# DSP2_EDMA_TPCC register map
Vendor: Texas Instruments
Registers are 32-bit, read-write, reset values left out (the file's numbers can be read two ways) unless marked. A register's access mark holds for its fields unless they carry their own. Offsets are as the file gives them; [hi:lo] are bit positions; {n}, {i} and the like mark numbered series; 'fields as' and 'values as' point back to an identical list.

## DSP2_EDMA_TPCC (part 2 of 2)
0x00 EDMA_TPCC_PID ro — Peripheral ID Register
  [31:0] REVISION — IP revision
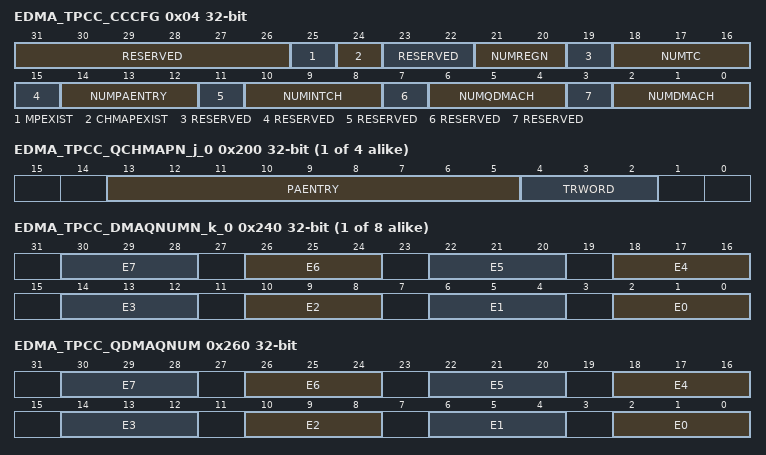
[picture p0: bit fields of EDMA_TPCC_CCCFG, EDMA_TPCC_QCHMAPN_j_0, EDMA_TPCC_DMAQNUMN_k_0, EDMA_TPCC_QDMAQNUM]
0x04 EDMA_TPCC_CCCFG ro — CC Configuration Register
  [31:26] RESERVED — Reads return 0's
  [25] MPEXIST — Memory Protection Existence
    0=No_memory_protection; 1=Memory_Protection_logic_included
  [24] CHMAPEXIST — Channel Mapping Existence
    0=No_Channel_mapping; 1=Channel_mapping_logic_included
  [23:22] RESERVED — Reads return 0's
  [21:20] NUMREGN — Number of MP and Shadow regions
    0=NUMREG0 (0 Regions); 1=NUMREG2 (2 Regions); 2=NUMREG8 (4 Regions); 3=NUMREG4 (8 Regions)
  [19] RESERVED — Reads return 0's
  [18:16] NUMTC — Number of Queues/Number of TCs
    {v}={v+1} TC/Event Queue (v=0..7)
  [15] RESERVED — Reads return 0's
  [14:12] NUMPAENTRY — Number of PaRAM entries
    0=NUMPARAMENTRIES32 (16 entries); 1=NUMPARAMENTRIES16 (32 entries); 2=NUMPARAMENTRIES64 (64 entries); 3=NUMPARAMENTRIES256 (128 entries); 4=NUMPARAMENTRIES512 (256 entries); 5=NUMPARAMENTRIES128 (512 entries)
  [11] RESERVED — Reads return 0's
  [10:8] NUMINTCH — Number of Interrupt Channels
    1=8 Interrupt channels; 2=16 Interrupt channels; 3=32 Interrupt channels; 4=64 Interrupt channels
  [7] RESERVED — reads return 0's
  [6:4] NUMQDMACH — Number of QDMA Channels
    0=No QDMA Channels; 1=2 QDMA Channels; 2=4 QDMA Channels; 3=6 QDMA Channels; 4=8 QDMA Channels
  [3] RESERVED — reads return 0's
  [2:0] NUMDMACH — Number of DMA Channels
    0=No DMA Channels; 1=4 DMA Channels; 2=8 DMA Channels; 3=16 DMA Channels; 4=32 DMA Channels; 5=64 DMA Channels
0xFC EDMA_TPCC_CLKGDIS access per field — Auto Clock Gate Disable
  [0] CLKGDIS rw
{0x100+4i} EDMA_TPCC_DCHMAPN_m_{i} access per field (i=0..63) — DMA Channel N Mapping Register
  [13:5] PAENTRY rw — PaRAM Entry number for DMA Channel N.
{0x200+4i} EDMA_TPCC_QCHMAPN_j_{i} access per field (i=0..3) — QDMA Channel N Mapping Register
  [13:5] PAENTRY rw — PaRAM Entry number for QDMA Channel N.
  [4:2] TRWORD rw — TRWORD points to the specific trigger word of the PaRAM Entry defined by PAENTRY. A write to the trigger word results in a QDMA Event being recognized.
{0x240+4i} EDMA_TPCC_DMAQNUMN_k_{i} access per field (i=0..7) — DMA Queue Number Register n Contains the Event queue number to be used for the corresponding DMA Channel.
  [4n+2:4n] E{n} rw (n=0..7) — DMA Queue Number for event #{n}
0x260 EDMA_TPCC_QDMAQNUM access per field — QDMA Queue Number Register Contains the Event queue number to be used for the corresponding QDMA Channel.
  [4n+2:4n] E{n} rw (n=0..7) — QDMA Queue Number for event #{n}
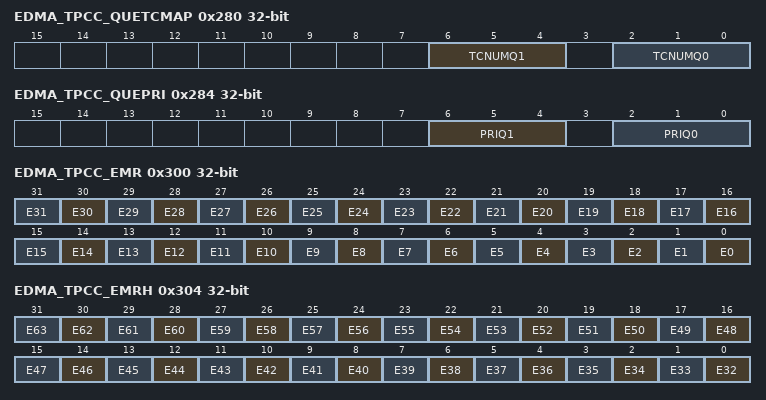
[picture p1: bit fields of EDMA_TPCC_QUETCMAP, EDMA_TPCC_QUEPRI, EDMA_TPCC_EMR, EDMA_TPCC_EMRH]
0x280 EDMA_TPCC_QUETCMAP access per field — Queue to TC Mapping
  [6:4] TCNUMQ1 rw — TC Number for Queue N: Defines the TC number that Event Queue N TRs are written to.
  [2:0] TCNUMQ0 rw — TC Number for Queue N: Defines the TC number that Event Queue N TRs are written to.
0x284 EDMA_TPCC_QUEPRI access per field — Queue Priority
  [6:4] PRIQ1 rw — Priority Level for Queue 1 Dictates the priority level used for the OPTIONS field programmation for Qn TRs. Sets the priority used for TC read and write commands.
  [2:0] PRIQ0 rw — Priority Level for Queue 0 Dictates the priority level used for the OPTIONS field programmation for Qn TRs. Sets the priority used for TC read and write commands.
0x300 EDMA_TPCC_EMR ro — Event Missed Register: The Event Missed register is set if 2 events are received without the first event being cleared or if a Null TR is serviced. Chained events (CER), Set Events (ESR), and normal events (ER) are treated individually. If any bit in the EMR register is set (and all errors (including / ) were previously clear), then an error will be signaled with TPCC error interrupt.
  [n] E{n} (n=0..31) — Event Missed #{n}
0x304 EDMA_TPCC_EMRH ro — Event Missed Register (High Part): The Event Missed register is set if 2 events are received without the first event being cleared or if a Null TR is serviced. Chained events (CER), Set Events (ESR), and normal events (ER) are treated individually. If any bit in the EMR register is set (and all errors (including / ) were previously clear), then an error will be signaled with TPCC error interrupt.
  [n-32] E{n} (n=32..63) — Event Missed #{n}
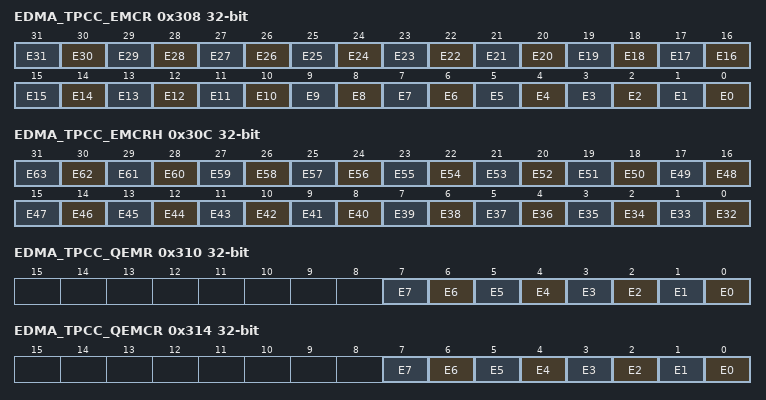
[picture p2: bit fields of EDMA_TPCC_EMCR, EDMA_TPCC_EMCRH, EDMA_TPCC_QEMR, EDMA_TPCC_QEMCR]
0x308 EDMA_TPCC_EMCR wo — Event Missed Clear Register: CPU write of '1' to the.En bit causes the .En bit to be cleared. CPU write of '0' has no effect.. All error bits must be cleared before additional error interrupts will be asserted by CC.
  [n] E{n} (n=0..31) — Event Missed Clear #{n}
0x30C EDMA_TPCC_EMCRH wo — Event Missed Clear Register (High Part): CPU write of '1' to the.En bit causes the .En bit to be cleared. CPU write of '0' has no effect. All error bits must be cleared before additional error interrupts will be asserted by CC.
  [n-32] E{n} (n=32..63) — Event Missed Clear #{n}
0x310 EDMA_TPCC_QEMR ro — QDMA Event Missed Register: The QDMA Event Missed register is set if 2 QDMA events are detected without the first event being cleared or if a Null TR is serviced. If any bit in the register is set (and all errors (including / ) were previously clear), then an error will be signaled with TPCC error interrupt.
  [n] E{n} (n=0..7) — Event Missed #{n}
0x314 EDMA_TPCC_QEMCR access per field — QDMA Event Missed Clear Register: CPU write of '1' to the.En bit causes the .En bit to be cleared. CPU write of '0' has no effect. All error bits must be cleared before additional error interrupts will be asserted by CC.
  [n] E{n} wo (n=0..7) — Event Missed Clear #{n}
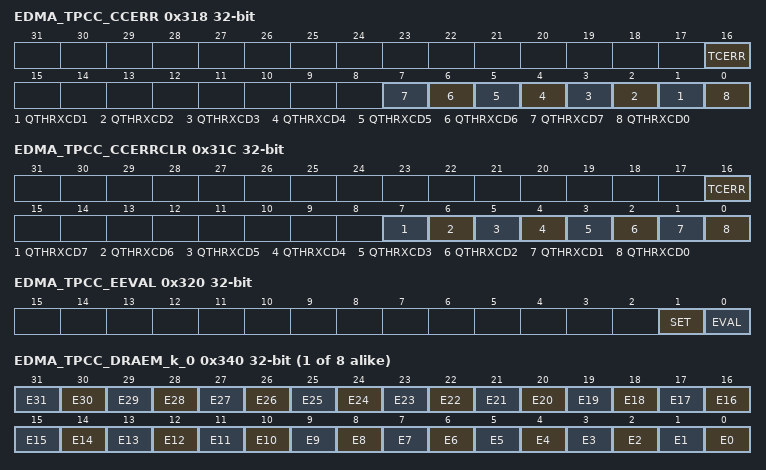
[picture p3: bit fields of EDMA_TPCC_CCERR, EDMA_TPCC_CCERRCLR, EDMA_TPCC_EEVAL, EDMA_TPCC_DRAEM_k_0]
0x318 EDMA_TPCC_CCERR ro — CC Error Register
  [16] TCERR — Transfer Completion Code ErrorTCERR can be cleared by writing a '1' to corresponding bit in register. If any bit in the register is set (and all errors were previously clear), then an error will be signaled with TPCC error interrupt. .
    0=Total number of allowed TCCs outstanding has not been reached; 1=Total number of allowed TCCs has been reached
  [n] QTHRXCD{n} (n=1..7) — Queue Threshold Error for Q{n}QTHRXCD{n} can be cleared by writing a '1' to corresponding bit in register. If any bit in the register is set (and all errors (including /) were previously clear), then an error will be signaled with the TPCC error interrupt. .
    0=Watermark/threshold has not been exceeded; 1=Watermark/threshold_has_been_exceeded
  [0] QTHRXCD0 — Queue Threshold Error for Q0:QTHRXCD0 can be cleared by writing a '1' to corresponding bit in register. If any bit in the register is set (and all errors (including /) were previously clear), then an error will be signaled with the TPCC error interrupt. .
    values as QTHRXCD1
0x31C EDMA_TPCC_CCERRCLR access per field — CC Error Clear Register
  [16] TCERR wo — Clear Error forEDMA_TPCC_CCERR[16] TR.Write 0x1 to clear the value of[16] TCERR. . Write 0x0 have no affect. .
  [7] QTHRXCD7 wo — Clear error forEDMA_TPCC_CCERR[7]QTHRXCD7Write 0x0 have no affect. . Write 0x1 to clear the values of QSTAT7.WM, QSTAT7.THRXCD,[7] QTHRXCD7 .
  [6] QTHRXCD6 wo — Clear error forEDMA_TPCC_CCERR[6] QTHRXCD6Write 0x0 have no affect. . Write 0x1 to clear the values of QSTAT6.WM, QSTAT6.THRXCD,[6]QTHRXCD6 .
  [5] QTHRXCD5 wo — Clear error forEDMA_TPCC_CCERR[5] QTHRXCD5Write 0x0 have no affect. . Write 0x1 to clear the values of QSTAT5.WM, QSTAT5.THRXCD,[5]QTHRXCD5 .
  [4] QTHRXCD4 wo — Clear error forEDMA_TPCC_CCERR[4] QTHRXCD4:Write 0x0 have no affect. . Write 0x1 to clear the values of QSTAT4.WM, QSTAT4.THRXCD,[4] QTHRXCD4 .
  [3] QTHRXCD3 wo — Clear error forEDMA_TPCC_CCERR[3] QTHRXCD3Write 0x1 to clear the values of QSTAT3.WM, QSTAT3.THRXCD,[3] QTHRXCD3 . Write 0x0 have no affect. .
  [2] QTHRXCD2 wo — Clear error forEDMA_TPCC_CCERR[2] QTHRXCD2Write 0x0 have no affect. . Write 0x1 to clear the values of QSTAT2.WM, QSTAT2.THRXCD,[2] QTHRXCD2 .
  [1] QTHRXCD1 wo — Clear error forEDMA_TPCC_CCERR[1] QTHRXCD1Write 0x1 to clear the values of QSTAT1.WM, QSTAT1.THRXCD,[1] QTHRXCD1 . Write 0x0 have no affect. .
  [0] QTHRXCD0 wo — Clear error forEDMA_TPCC_CCERR[0] QTHRXCD0Write 0x0 have no affect. . Write 0x1 to clear the values of QSTAT0.WM, QSTAT0.THRXCD,[0] QTHRXCD0 .
0x320 EDMA_TPCC_EEVAL access per field — Error Eval Register
  [1] SET wo — Error Interrupt SetCPU writes 0x0 has no effect. . CPU writes 0x1 to the SET bit causes the TPCC error interrupt to be pulsed regardless of state of/, , or . .
  [0] EVAL wo — Error Interrupt EvaluateCPU writes 0x0 has no effect. . CPU writes 0x1 to the EVAL bit causes the TPCC error interrupt to be pulsed if any errors have not been cleared in the/, , or registers. The CPU must also write 0x1 after any error interrupts are serviced in order for subsequent interrupts to be asserted. .
{0x340+8i} EDMA_TPCC_DRAEM_k_{i} (i=0..7) — DMA Region Access enable for bit N in Region M: En = 0 : Accesses via Region M address space to Bit N in any DMA Channel Register are not allowed. Reads will return 'b0 on Bit N and writes will not modify the state of bit N. Enabled interrupt bits for bit N do not contribute to the generation of the TPCC region M interrupt. En = 1 : Accesses via Region M address space to Bit N in any DMA Channel Register are allowed. Reads will return the value from Bit N and writes will modify the state of bit N. Enabled interrupt bits for bit N do contribute to the generation of the TPCC region M interrupt.
  [n] E{n} (n=0..31) — DMA Region Access enable for Region M, bit #{n}
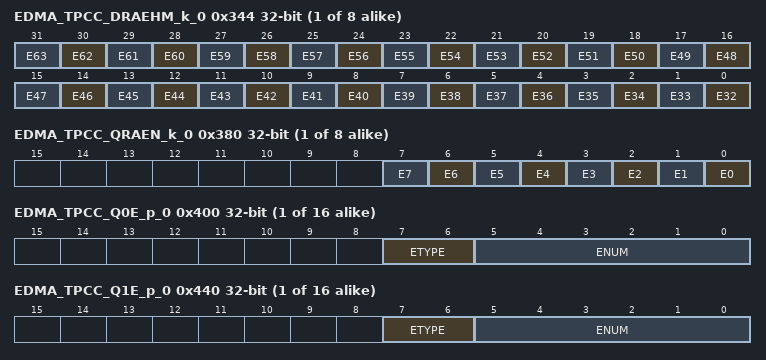
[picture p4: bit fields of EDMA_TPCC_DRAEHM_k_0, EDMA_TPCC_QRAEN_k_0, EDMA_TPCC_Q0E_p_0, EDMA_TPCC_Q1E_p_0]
{0x344+8i} EDMA_TPCC_DRAEHM_k_{i} (i=0..7) — DMA Region Access enable for bit N in Region M: En = 0 : Accesses via Region M address space to Bit N in any DMA Channel Register are not allowed. Reads will return 'b0 on Bit N and writes will not modify the state of bit N. Enabled interrupt bits for bit N do not contribute to the generation of the TPCC region M interrupt. En = 1 : Accesses via Region M address space to Bit N in any DMA Channel Register are allowed. Reads will return the value from Bit N and writes will modify the state of bit N. Enabled interrupt bits for bit N do contribute to the generation of the TPCC region M interrupt. En = 0 : Accesses via Region M address space to Bit N in any DMA Channel Register are not allowed. Reads will return 'b0 on Bit N and writes will not modify the state of bit N. Enabled interrupt bits for bit N do not contribute to the generation of the TPCC region M interrupt. En = 1 : Accesses via Region M address space to Bit N in any DMA Channel Register are allowed. Reads will return the value from Bit N and writes will modify the state of bit N. Enabled interrupt bits for bit N do contribute to the generation of the TPCC region M interrupt.
  [n-32] E{n} (n=32..63) — DMA Region Access enable for Region M, bit #{n}
{0x380+4i} EDMA_TPCC_QRAEN_k_{i} access per field (i=0..7) — QDMA Region Access enable for bit N in Region M: En = 0 : Accesses via Region M address space to Bit N in any QDMA Channel Register are not allowed. Reads will return 'b0 on Bit N and writes will not modify the state of bit N. Enabled interrupt bits for bit N do not contribute to the generation of the TPCC region M interrupt. En = 1 : Accesses via Region M address space to Bit N in any QDMA Channel Register are allowed. Reads will return the value from Bit N and writes will modify the state of bit N. Enabled interrupt bits for bit N do contribute to the generation of the TPCC region n interrupt.
  [n] E{n} rw (n=0..7) — QDMA Region Access enable for Region M, bit #{n}
{0x400+4i} EDMA_TPCC_Q0E_p_{i} ro (i=0..15) — Event Queue Entries Diagram for Queue 0 - Entry 0 through Entry 15
  [7:6] ETYPE — Event Type: Specifies the specific Event Type for the given entry in the Event Queue.
  [5:0] ENUM — Event Number: Specifies the specific Event Number for the given entry in the Event Queue. For DMA Channel events (EDMA_TPCC_ER/EDMA_TPCC_ESR/EDMA_TPCC_CER), ENUM will range between 0 and NUM_DMACH (up to 63). For QDMA Channel events (EDMA_TPCC_QER), ENUM will range between 0 and NUM_QDMACH (up to 7).
{0x440+4i} EDMA_TPCC_Q1E_p_{i} ro (i=0..15) — Event Queue Entries Diagram for Queue 1 - Entry 0 through Entry 15
  [7:6] ETYPE — Event Type: Specifies the specific Event Type for the given entry in the Event Queue.
  [5:0] ENUM — Event Number: Specifies the specific Event Number for the given entry in the Event Queue. For DMA Channel events (EDMA_TPCC_ER / EDMA_TPCC_ESR / EDMA_TPCC_CER), ENUM will range between 0 and NUM_DMACH (up to 63). For QDMA Channel events (EDMA_TPCC_QER), ENUM will range between 0 and NUM_QDMACH (up to 7).
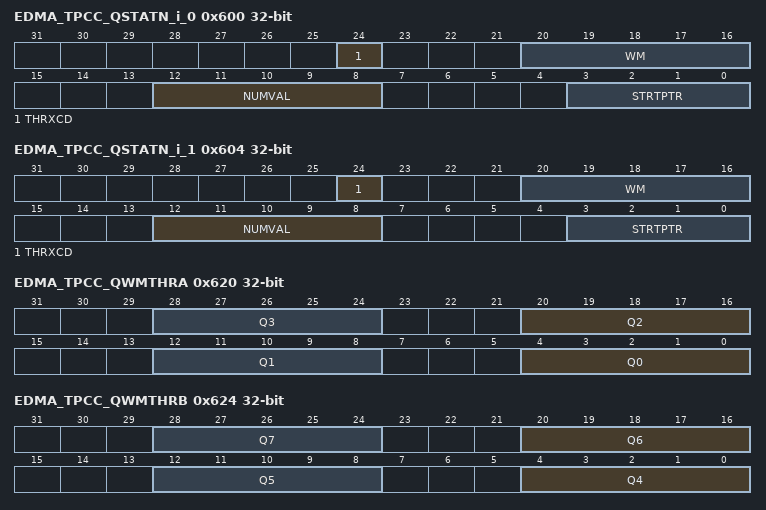
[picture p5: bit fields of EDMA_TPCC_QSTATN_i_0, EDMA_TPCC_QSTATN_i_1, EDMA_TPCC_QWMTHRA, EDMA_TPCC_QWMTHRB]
0x600 EDMA_TPCC_QSTATN_i_0 access not given — QSTATn Register Set
  [24] THRXCD ro — Threshold ExceededTHRXCD is cleared via. WMCLRn bit. .
    0=Threshold specified by QWMTHR(A|B).Qn has not been exceeded; 1=Threshold specified by QWMTHR(A|B).Qn has been exceeded
  [20:16] WM ro — Watermark for Maximum Queue Usage: Watermark tracks the most entries that have been in QueueN since reset or since the last time that the watermark (WM) was cleared. QSTATn. WM is cleared via EDMA_TPCC_CCERR.WMCLRn bit. Legal values:
    0=empty; 16=full
  [12:8] NUMVAL ro — Number of Valid Entries in QueueN: Represents the total number of entries residing in the Queue Manager FIFO at a given instant. Always enabled. Legal values: = 0x0 (empty) to 0x10 (full)
    0=empty; 16=full
  [3:0] STRTPTR ro — Start Pointer: Represents the offset to the head entry of QueueN, in units of *entries*. Always enabled. Legal values:
    0=0th_entry; 15=15th_entry
0x604 EDMA_TPCC_QSTATN_i_1 access not given — QSTATn Register Set
  fields as EDMA_TPCC_QSTATN_i_0
0x620 EDMA_TPCC_QWMTHRA access per field — Queue Threshold A, for Q[3:0]:.QTHRXCDn and QSTATn[24] THRXCD error bit is set when the number of Events in QueueN at an instant in time (visible via QSTATn[12:8] NUMVAL) equals or exceeds the value specified by .Qn. Legal values = 0x0 (ever used?) to 0x10 (ever full?) A value of 0x11 disables threshold errors.
  [8n+4:8n] Q{n} rw (n=0..3) — Queue Threshold for Q{n} value
0x624 EDMA_TPCC_QWMTHRB access per field — Queue Threshold B, for Q[7:4]:.QTHRXCDn and QSTATn[24]THRXCD error bit is set when the number of Events in QueueN at an instant in time (visible via QSTATn[12:8] NUMVAL) equals or exceeds the value specified by QWMTHRB.Qn. Legal values = 0x0 (ever used?) to 0x10 (ever full?) A value of 0x11 disables threshold errors.
  [8n-28:8n-32] Q{n} rw (n=4..7) — Queue Threshold for Q{n} value (unused in the context of IVAHD)
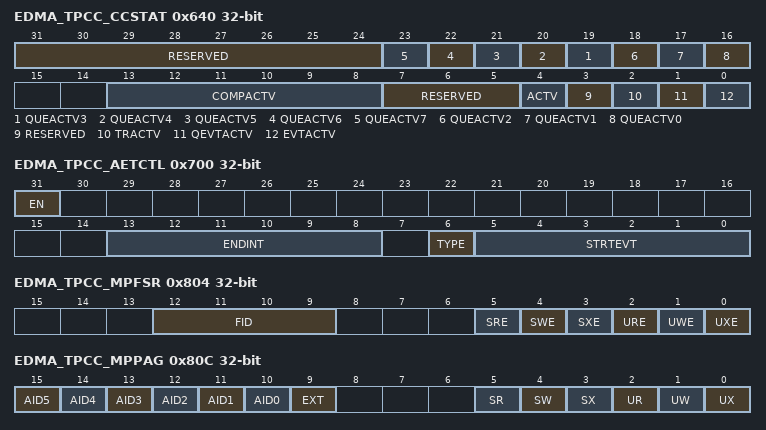
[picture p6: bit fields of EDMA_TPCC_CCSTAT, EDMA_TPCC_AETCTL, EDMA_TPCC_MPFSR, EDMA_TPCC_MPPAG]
0x640 EDMA_TPCC_CCSTAT access not given — CC Status Register
  [31:24] RESERVED ro — reads return 0's
  [n+16] QUEACTV{n} ro (n=3..7) — Queue {n} Active
    0=No_Evts_are_queued_in_Q{n}; 1=At_least_one_TR_is_queued_in_Q{n}
  [18] QUEACTV2 ro — Queue 2 Active QUEACTV2 = 0 : No Evts are queued in Q2. QUEACTV2 = 1 : At least one TR is queued in Q2.
    0=QUEACTV2_0; 1=QUEACTV2_1
  [17] QUEACTV1 ro — Queue 1 Active
    0=No_Evts_are_queued_in_Q1; 1=At_least_one_TR_is_queued_in_Q1
  [16] QUEACTV0 ro — Queue 0 Active
    0=No_Evts_are_queued_in_Q0; 1=At_least_one_TR_is_queued_in_Q0
  [13:8] COMPACTV ro — Completion Request Active: Counter that tracks the total number of completion requests submitted to the TC. The counter increments when a TR is submitted with TCINTEN or TCCHEN set to '1'. The counter decrements for every valid completion code received from any of the external TCs. The CC will not service new TRs if COMPACTV count is already at the limit.... .
    0=No_completion_requests_outstanding; 1=Total of '1' completion request outstanding; 63=Total of 63 completion requests are outstanding. No additional TRs will be submitted until count is less than 63.
  [7:5] RESERVED ro — reads return 0's
  [4] ACTV ro — Channel Controller Active Channel Controller Active is a logical-OR of each of the *ACTV signals. The ACTV bit must remain high through the life of a:
    0=Channel_is_idle; 1=Channel_is_busy
  [3] RESERVED ro — reads return 0's
  [2] TRACTV ro — Transfer Request Active TRACTV = 0 : Transfer Request processing/submission logic is inactive. TRACTV = 1 : Transfer Request processing/submission logic is active.
  [1] QEVTACTV ro — QDMA Event Active
    0=QDMA_CC._0 (No enabled QDMA Events are active within the CC.); 1=DMA_CC._1 (At least one enabled DMA Event (, , , ) is active within the CC.)
  [0] EVTACTV ro — DMA Event Active
    0=DMA_CC._0 (No enabled DMA Events are active within the CC.); 1=DMA_CC._1 (At least one enabled DMA Event (, , , ) is active within the CC.)
0x700 EDMA_TPCC_AETCTL access per field — Advanced Event Trigger Control
  [31] EN rw — AET Enable
    0=AET_event_generation_is_disabled; 1=AET_event_generation_is_enabled
  [13:8] ENDINT rw — AET End Interrupt: Dictates the completion interrupt number that will force the tpcc_aet signal to be deasserted (low)
  [6] TYPE rw — AET Event Type
    0=STARTEVT_DMA_0 (Event specified by STARTEVT applies to DMA Events (set by, , or )); 1=STARTEVT_QDMA_1 (Event specified by STARTEVT applies to QDMA Events)
  [5:0] STRTEVT rw — AET Start Event: Dictates the Event Number that will force the tpcc_aet signal to be asserted (high)
0x704 EDMA_TPCC_AETSTAT access not given — Advanced Event Trigger Stat
  [0] STAT ro — AET Status
    0=tpcc_aet_is_currently_low; 1=tpcc_aet_is_currently_high
0x708 EDMA_TPCC_AETCMD access per field — AET Command
  [0] CLR wo — AET Clear commandCPU writes 0x0 has no effect. . CPU writes 0x1 to the CLR bit causes the tpcc_aet output signal and[0]STAT register to be cleared. .
0x800 EDMA_TPCC_MPFAR ro — MMemory Protection Fault Address
  [31:0] FADDR — Fault Address: 32-bit read-only status register containing the faulting address when a mMemory protection violation is detected. This register can only be cleared via theEDMA_TPCC_MPFCR.
0x804 EDMA_TPCC_MPFSR access not given — Memory Protection Fault Status Register
  [12:9] FID ro — Faulted ID: FID register contains valid info if any of the MP error bits (UXE, UWE, URE, SXE, SWE, SRE) are non-zero (i.e., if an error has been detected.) The FID field contains the VBus PrivID for the specific request/requestor that resulted in a MP Error.
  [5] SRE ro — Supervisor Read Error
    0=No_error_detected; 1=MP_SR_1 (Supervisor level task attempted to Read from a MP Page without SR permissions.)
  [4] SWE ro — Supervisor Write Error
    0=No_error_detected; 1=MP_SW_1 (Supervisor level task attempted to Write to a MP Page without SW permissions.)
  [3] SXE ro — Supervisor Execute Error
    0=No_error_detected; 1=MP_SX_1 (Supervisor level task attempted to Execute from a MP Page without SX permissions.)
  [2] URE ro — User Read Error
    0=No_error_detected; 1=MP_UR_1 (User level task attempted to Read from a MP Page without UR permissions.)
  [1] UWE ro — User Write Error
    0=No_error_detected; 1=MP_UW_1 (User level task attempted to Write to a MP Page without UW permissions.)
  [0] UXE ro — User Execute Error
    0=No_error_detected; 1=MP_UX_1 (User level task attempted to Execute from a MP Page without UX permissions.)
0x808 EDMA_TPCC_MPFCR access per field — Memory Protection Fault Command Register
  [0] MPFCLR wo — Fault Clear register
    0=has_no_effect; 1=to the MPFCLR bit causes any error conditions stored in and registers to be cleared
0x80C EDMA_TPCC_MPPAG access per field — Memory Protection Page Attribute for Global registers
  [15] AID5 rw — Allowed ID 5
    0=(UW,_UR,_SW,_SR).0_0 (VBus requests with PrivID == '5' are not allowed regardless of permission settings (UW, UR, SW, SR).0); 1=(UW,_UR,_SW,_SR)._1 (VBus requests with PrivID == '5' are permitted if access type is allowed as defined by permission settings (UW, UR, SW, SR).)
  [n+10] AID{n} rw (n=0..4) — Allowed ID {n}
    0=(UW,_UR,_SW,_SR)._0 (VBus requests with PrivID == '{n}' are not allowed regardless of permission settings (UW, UR, SW, SR).); 1=(UW,_UR,_SW,_SR)._1 (VBus requests with PrivID == '{n}' are permitted if access type is allowed as defined by permission settings (UW, UR, SW, SR).)
  [9] EXT rw — External Allowed ID
    0=(UW,_UR,_SW,_SR)._0 (VBus requests with PrivID = '6' are not allowed regardless of permission settings (UW, UR, SW, SR).); 1=(UW,_UR,_SW,_SR)._1 (VBus requests with PrivID = '6' are permitted if access type is allowed as defined by permission settings (UW, UR, SW, SR).)
  [5] SR rw — Supervisor Read permission
    0=Supervisor read accesses are not allowed; 1=Supervisor_write_accesses_are_allowed
  [4] SW rw — Supervisor Write permission
    0=Supervisor write accesses are not allowed; 1=Supervisor_write_accesses_are_allowed
  [3] SX rw — Supervisor Execute permission
    0=Supervisor execute accesses are not allowed; 1=Supervisor_execute_accesses_are_allowed
  [2] UR rw — User Read permission
    0=User_read_accesses_are_not_allowed; 1=User_write_accesses_are_allowed
  [1] UW rw — User Write permission
    0=User_write_accesses_are_not_allowed; 1=User_write_accesses_are_allowed
  [0] UX rw — User Execute permission
    0=User_execute_accesses_are_not_allowed; 1=User_execute_accesses_are_allowed
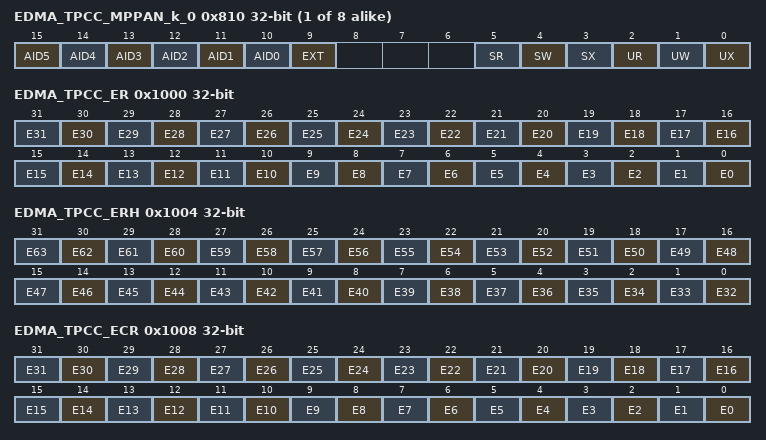
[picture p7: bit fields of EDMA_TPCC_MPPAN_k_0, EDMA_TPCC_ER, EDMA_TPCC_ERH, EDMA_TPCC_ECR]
{0x810+4i} EDMA_TPCC_MPPAN_k_{i} access per field (i=0..7) — P Permission Attribute for DMA Region n
  [n+10] AID{n} rw (n=1..5) — Allowed ID {n}
    values as EDMA_TPCC_MPPAG.AID0
  [10] AID0 rw — Allowed ID 0: AID0 = 0 : VBus requests with PrivID == '0' are not allowed regardless of permission settings (UW, UR, SW, SR). AID0 = 1 : VBus requests with PrivID == '0' are permitted if access type is allowed as defined by permission settings (UW, UR, SW, SR).
  [9] EXT rw — External Allowed ID
    values as EDMA_TPCC_MPPAG.EXT
  [5] SR rw — Supervisor Read permission
    values as EDMA_TPCC_MPPAG.SR
  [4] SW rw — Supervisor Write permission
    values as EDMA_TPCC_MPPAG.SW
  [3] SX rw — Supervisor Execute permission
    values as EDMA_TPCC_MPPAG.SX
  [2] UR rw — User Read permission
    values as EDMA_TPCC_MPPAG.UR
  [1] UW rw — User Write permission
    values as EDMA_TPCC_MPPAG.UW
  [0] UX rw — User Execute permission
    0=User_execute_accesses_are_not_allowed; 0=User_execute_accesses_are_allowed
0x1000 EDMA_TPCC_ER ro — Event Register: If .En bit is set and the .En bit is also set, then the corresponding DMA channel is prioritized vs. other pending DMA events for submission to the TC. .En bit is set when the input event #n transitions from inactive (low) to active (high), regardless of the state of .En bit. .En bit is cleared when the corresponding event is prioritized and serviced. If the .En bit is already set and a new inactive to active transition is detected on the input event #n input AND the corresponding bit in the register is set, then the corresponding bit in the Event Missed Register is set. Event N can be cleared via sw by writing a '1' to the pseudo-register.
  [n] E{n} (n=0..31) — Event #{n}
0x1004 EDMA_TPCC_ERH ro — Event Register (High Part): If .En bit is set and the .En bit is also set, then the corresponding DMA channel is prioritized vs. other pending DMA events for submission to the TC. .En bit is set when the input event #n transitions from inactive (low) to active (high), regardless of the state of .En bit. .En bit is cleared when the corresponding event is prioritized and serviced. If the .En bit is already set and a new inactive to active transition is detected on the input event #n input AND the corresponding bit in the register is set, then the corresponding bit in the Event Missed Register is set. Event N can be cleared via sw by writing a '1' to the pseudo-register.
  [n-32] E{n} (n=32..63) — Event #{n}
0x1008 EDMA_TPCC_ECR wo — Event Clear Register: CPU write of '1' to the .En bit causes the .En bit to be cleared. CPU write of '0' has no effect.
  [n] E{n} (n=0..31) — Event #{n}
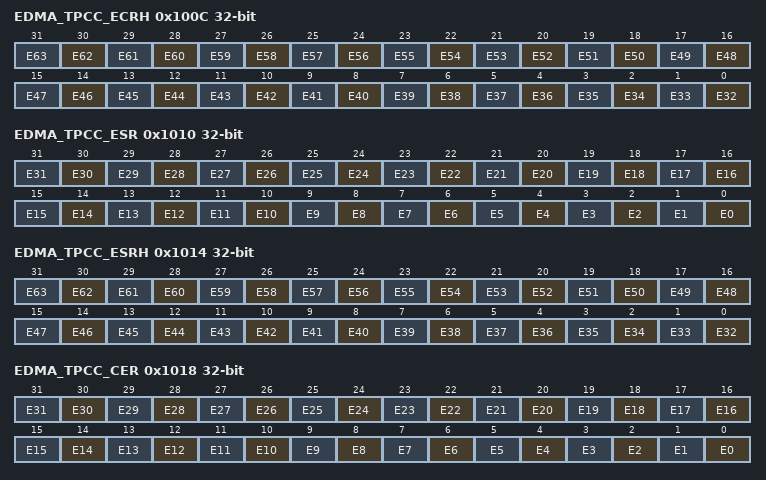
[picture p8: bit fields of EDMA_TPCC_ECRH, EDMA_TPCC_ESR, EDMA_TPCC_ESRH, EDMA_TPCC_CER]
0x100C EDMA_TPCC_ECRH wo — Event Clear Register (High Part): CPU write of '1' to the .En bit causes the .En bit to be cleared. CPU write of '0' has no effect.
  [n-32] E{n} (n=32..63) — Event #{n}
0x1010 EDMA_TPCC_ESR wo — Event Set Register: CPU write of '1' to the .En bit causes the .En bit to be set. CPU write of '0' has no effect.
  [n] E{n} (n=0..31) — Event #{n}
0x1014 EDMA_TPCC_ESRH wo — Event Set Register (High Part) CPU write of '1' to the .En bit causes the .En bit to be set. CPU write of '0' has no effect.
  [n-32] E{n} (n=32..63) — Event #{n}
0x1018 EDMA_TPCC_CER ro — Chained Event Register: If .En bit is set (regardless of state of .En), then the corresponding DMA channel is prioritized vs. other pending DMA events for submission to the TC. .En bit is set when a chaining completion code is returned from one of the 3PTCs via the completion interface, or is generated internally via Early Completion path. .En bit is cleared when the corresponding event is prioritized and serviced. If the .En bit is already set and the corresponding chaining completion code is returned from the TC, then the corresponding bit in the Event Missed Register is set. .En cannot be set or cleared via software.
  [n] E{n} (n=0..31) — Event #{n}
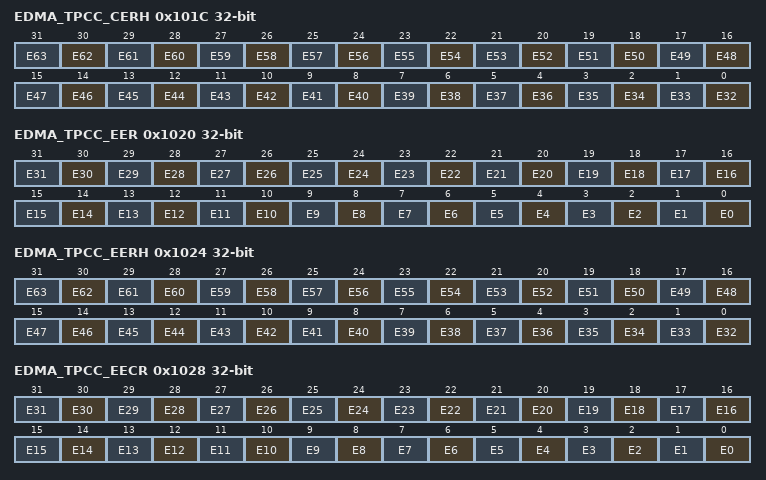
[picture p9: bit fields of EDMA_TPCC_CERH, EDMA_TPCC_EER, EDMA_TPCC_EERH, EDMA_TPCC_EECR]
0x101C EDMA_TPCC_CERH ro — Chained Event Register (High Part): If .En bit is set (regardless of state of .En), then the corresponding DMA channel is prioritized vs. other pending DMA events for submission to the TC. .En bit is set when a chaining completion code is returned from one of the 3PTCs via the completion interface, or is generated internally via Early Completion path. .En bit is cleared when the corresponding event is prioritized and serviced. If the .En bit is already set and the corresponding chaining completion code is returned from the TC, then the corresponding bit in the Event Missed Register is set. .En cannot be set or cleared via software.
  [n-32] E{n} (n=32..63) — Event #{n}
0x1020 EDMA_TPCC_EER ro — Event Enable Register: Enables DMA transfers for.En pending events. .En is set based on externally asserted events (via tpcc_eventN_pi). This register has no effect on Chained Event Register () or Event Set Register (). Note that if a bit is set in .En while .En is disabled, no action is taken. If .En is enabled at a later point (and .En has not been cleared via SW) then the event will be recognized as a valid 'TR Sync' .En is not directly writeable. Events can be enabled via writes to and can be disabled via writes to register. .En = 0: .En is not enabled to trigger DMA transfers. .En = 1: .En is enabled to trigger DMA transfers.
  [n] E{n} (n=0..31) — Event #{n}
0x1024 EDMA_TPCC_EERH ro — Event Enable Register (High Part): Enables DMA transfers for .En pending events. .En is set based on externally asserted events (via tpcc_eventN_pi). This register has no effect on Chained Event Register () or Event Set Register (). Note that if a bit is set in .En while .En is disabled, no action is taken. If .En is enabled at a later point (and .En has not been cleared via SW) then the event will be recognized as a valid 'TR Sync' .En is not directly writeable. Events can be enabled via writes to and can be disabled via writes to register. .En = 0: .En is not enabled to trigger DMA transfers. .En = 1: .En is enabled to trigger DMA transfers.
  [n-32] E{n} (n=32..63) — Event #{n}
0x1028 EDMA_TPCC_EECR wo — Event Enable Clear Register CPU writes of '1' to the .En bit causes the .En bit to be cleared. CPU writes of '0' has no effect..
  [n] E{n} (n=0..31) — Event #{n}
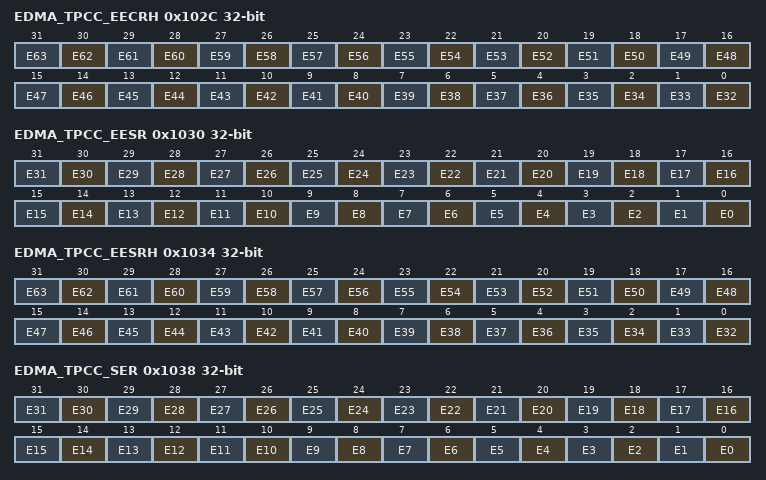
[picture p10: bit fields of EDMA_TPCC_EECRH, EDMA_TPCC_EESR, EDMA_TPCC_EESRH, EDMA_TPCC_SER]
0x102C EDMA_TPCC_EECRH wo — Event Enable Clear Register (High Part) CPU writes of '1' to the .En bit causes the EERH.En bit to be cleared. CPU writes of '0' has no effect..
  [n-32] E{n} (n=32..63) — Event #{n}
0x1030 EDMA_TPCC_EESR wo — Event Enable Set Register CPU write of '1' to the .En bit causes the .En bit to be set. CPU writes of '0' has no effect..
  [n] E{n} (n=0..31) — Event #{n}
0x1034 EDMA_TPCC_EESRH wo — Event Enable Set Register (High Part) CPU writes of '1' to the .En bit causes the .En bit to be set. CPU writes of '0' has no effect..
  [n-32] E{n} (n=32..63) — Event #{n}
0x1038 EDMA_TPCC_SER ro — Secondary Event Register The secondary event register is used along with the Event Register () to provide information on the state of an Event. En = 0 : Event is not currently in the Event Queue. En = 1 : Event is currently stored in Event Queue. Event arbiter will not prioritize additional events.
  [n] E{n} (n=0..31) — Event #{n}
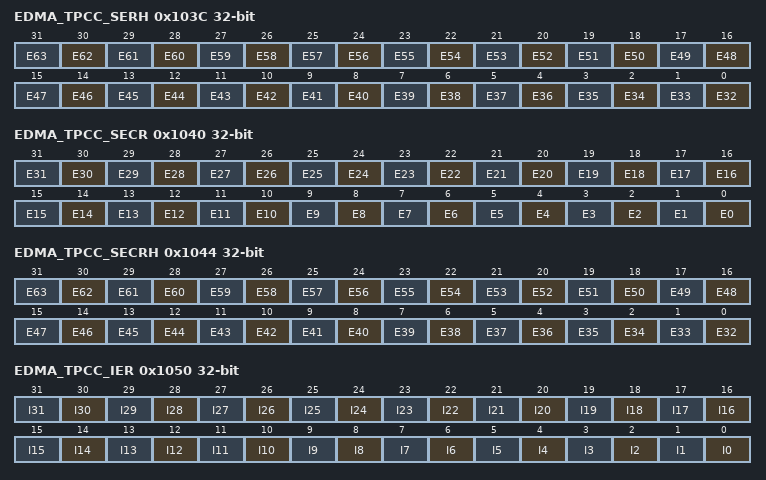
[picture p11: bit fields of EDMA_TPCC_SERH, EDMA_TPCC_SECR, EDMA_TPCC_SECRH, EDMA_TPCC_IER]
0x103C EDMA_TPCC_SERH ro — Secondary Event Register (High Part) The secondary event register is used along with the Event Register () to provide information on the state of an Event. En = 0 : Event is not currently in the Event Queue. En = 1 : Event is currently stored in Event Queue. Event arbiter will not prioritize additional events.
  [n-32] E{n} (n=32..63) — Event #{n}
0x1040 EDMA_TPCC_SECR wo — Secondary Event Clear Register The secondary event clear register is used to clear the status of the registers. CPU write of '1' to the .En bit clears the register. CPU write of '0' has no effect.
  [n] E{n} (n=0..31) — Event #{n}
0x1044 EDMA_TPCC_SECRH wo — Secondary Event Clear Register (High Part) The secondary event clear register is used to clear the status of the registers. CPU write of '1' to the .En bit clears the register. CPU write of '0' has no effect.
  [n-32] E{n} (n=32..63) — Event #{n}
0x1050 EDMA_TPCC_IER ro — Int Enable Register .In is not directly writeable. Interrupts can be enabled via writes to and can be disabled via writes to register. . In = 0: .In is NOT enabled for interrupts. . In = 1: .In IS enabled for interrupts.
  [n] I{n} (n=0..31) — Interrupt associated with TCC #{n}
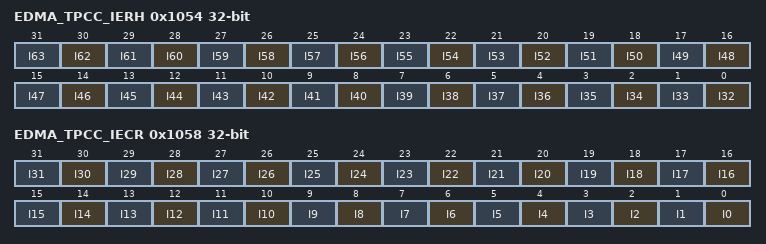
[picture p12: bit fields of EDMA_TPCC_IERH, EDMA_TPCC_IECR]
0x1054 EDMA_TPCC_IERH ro — Int Enable Register (High Part) .In is not directly writeable. Interrupts can be enabled via writes to and can be disabled via writes to register. . In = 0: .In is NOT enabled for interrupts. . In = 1: .In IS enabled for interrupts.
  [n-32] I{n} (n=32..63) — Interrupt associated with TCC #{n}
0x1058 EDMA_TPCC_IECR wo — Int Enable Clear Register CPU writes of '1' to the .In bit causes the .In bit to be cleared. CPU writes of '0' has no effect..
  [n] I{n} (n=0..31) — Interrupt associated with TCC #{n}
